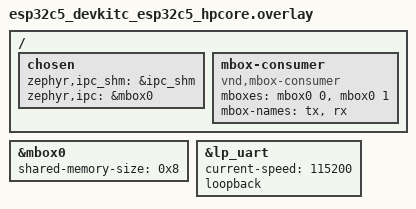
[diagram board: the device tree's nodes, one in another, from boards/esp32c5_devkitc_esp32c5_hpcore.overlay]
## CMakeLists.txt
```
# SPDX-License-Identifier: Apache-2.0

cmake_minimum_required(VERSION 3.28.0)
find_package(Zephyr REQUIRED HINTS $ENV{ZEPHYR_BASE})
project(lp_uart_lpcore)

target_sources(app PRIVATE src/main.c)
```

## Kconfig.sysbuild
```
# Copyright (c) 2026 Espressif Systems (Shanghai) Co., Ltd.
# SPDX-License-Identifier: Apache-2.0

source "share/sysbuild/Kconfig"

config ULP_REMOTE_BOARD
	string
	default "esp32c6_devkitc/esp32c6/lpcore" if $(BOARD) = "esp32c6_devkitc"
	default "esp32c5_devkitc/esp32c5/lpcore" if $(BOARD) = "esp32c5_devkitc"
```

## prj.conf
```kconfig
CONFIG_ZTEST=y
CONFIG_MBOX=y
CONFIG_SOC_FAMILY_ESPRESSIF_ULP_ENABLED=y
```

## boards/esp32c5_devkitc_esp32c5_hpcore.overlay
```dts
/*
 * Copyright (c) 2026 Espressif Systems (Shanghai) Co., Ltd.
 *
 * SPDX-License-Identifier: Apache-2.0
 */

/ {
	chosen {
		zephyr,ipc_shm = &ipc_shm;
		zephyr,ipc = &mbox0;
	};

	mbox-consumer {
		compatible = "vnd,mbox-consumer";
		mboxes = <&mbox0 0>, <&mbox0 1>;
		mbox-names = "tx", "rx";
	};
};

&mbox0 {
	status = "okay";
	shared-memory-size = <0x8>;
};

&lp_uart {
	status = "okay";
	current-speed = <115200>;
	loopback;
};
```

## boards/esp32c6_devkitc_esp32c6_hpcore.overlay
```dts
/*
 * Copyright (c) 2026 Espressif Systems (Shanghai) Co., Ltd.
 *
 * SPDX-License-Identifier: Apache-2.0
 */

/ {
	chosen {
		zephyr,ipc_shm = &ipc_shm;
		zephyr,ipc = &mbox0;
	};

	mbox-consumer {
		compatible = "vnd,mbox-consumer";
		mboxes = <&mbox0 0>, <&mbox0 1>;
		mbox-names = "tx", "rx";
	};
};

&mbox0 {
	shared-memory-size = <0x8>;
};

&lp_uart {
	current-speed = <115200>;
	loopback;
	status = "okay";
};
```

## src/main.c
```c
/*
 * Copyright (c) 2026 Espressif Systems (Shanghai) Co., Ltd.
 *
 * SPDX-License-Identifier: Apache-2.0
 */

/*
 * HP-core side of the LP UART loopback test.
 *
 * The LP core runs an LP-UART internal-loopback self-test and reports the
 * result word over the mailbox. This side waits for that word and asserts on
 * it, so the verdict is produced on the HP console without any external wiring.
 */

#include <zephyr/kernel.h>
#include <zephyr/ztest.h>
#include <zephyr/drivers/mbox.h>
#include <string.h>

#define LP_RESULT_PASS 0xA5A5A5A5U

static K_SEM_DEFINE(rx_sem, 0, 1);
static volatile uint32_t lp_result;

static void mbox_cb(const struct device *dev, mbox_channel_id_t channel_id, void *user_data,
		    struct mbox_msg *data)
{
	uint32_t value = 0;

	if ((data == NULL) || (data->data == NULL)) {
		return;
	}

	memcpy(&value, data->data, MIN(data->size, sizeof(value)));
	lp_result = value;
	k_sem_give(&rx_sem);
}

ZTEST(lp_uart_lpcore, test_lp_loopback_result)
{
	const struct mbox_dt_spec rx_channel = MBOX_DT_SPEC_GET(DT_PATH(mbox_consumer), rx);
	int ret;

	ret = mbox_register_callback_dt(&rx_channel, mbox_cb, NULL);
	zassert_ok(ret, "mbox_register_callback failed: %d", ret);

	ret = mbox_set_enabled_dt(&rx_channel, 1);
	zassert_ok(ret, "mbox_set_enabled failed: %d", ret);

	ret = k_sem_take(&rx_sem, K_SECONDS(5));
	zassert_ok(ret, "timed out waiting for LP core result");

	zassert_equal(lp_result, LP_RESULT_PASS,
		      "LP core reported LP-UART loopback failure (0x%08x)", lp_result);
}

ZTEST_SUITE(lp_uart_lpcore, NULL, NULL, NULL, NULL, NULL);
```
